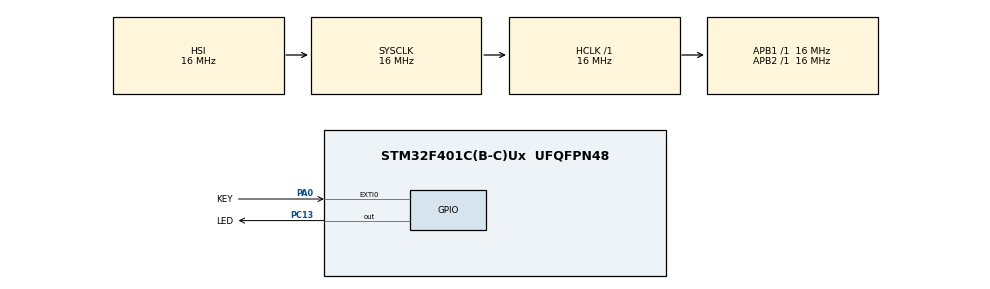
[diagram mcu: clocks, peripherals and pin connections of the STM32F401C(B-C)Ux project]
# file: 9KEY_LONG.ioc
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Mcu.Family=STM32F4
Mcu.Name=STM32F401C(B-C)Ux
Mcu.Package=UFQFPN48
NVIC.PriorityGroup=NVIC_PRIORITYGROUP_4
PA0-WKUP.GPIO_Label=KEY
PA0-WKUP.GPIO_PuPd=GPIO_PULLUP
PA0-WKUP.Signal=GPXTI0
PA13.Mode=Serial_Wire
PA13.Signal=SYS_JTMS-SWDIO
PA14.Mode=Serial_Wire
PA14.Signal=SYS_JTCK-SWCLK
PC13-ANTI_TAMP.GPIO_Label=LED
PC13-ANTI_TAMP.PinState=GPIO_PIN_SET
PC13-ANTI_TAMP.Signal=GPIO_Output
ProjectManager.HeapSize=0x200
ProjectManager.StackSize=0x400
ProjectManager.TargetToolchain=STM32CubeIDE
RCC.AHBFreq_Value=16000000
RCC.APB1Freq_Value=16000000
RCC.APB2Freq_Value=16000000
RCC.CortexFreq_Value=16000000
RCC.HSE_VALUE=25000000
RCC.HSI_VALUE=16000000
RCC.LSE_VALUE=32768
RCC.SYSCLKFreq_VALUE=16000000
RCC.VCOOutputFreq_Value=192000000
board=custom

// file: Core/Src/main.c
/* USER CODE BEGIN Header */
/**
  ******************************************************************************
  * @file           : main.c
  * @brief          : Main program body
  ******************************************************************************
  * @attention
  *
  * Copyright (c) 2022 STMicroelectronics.
  * All rights reserved.
  *
  * This software is licensed under terms that can be found in the LICENSE file
  * in the root directory of this software component.
  * If no LICENSE file comes with this software, it is provided AS-IS.
  *
  ******************************************************************************
  */
/* USER CODE END Header */
#include "main.h"

/* USER CODE BEGIN PTD */
typedef struct{
	uint32_t time;
	pinState level;
} buttonDef;
buttonDef key[3];

/* USER CODE END PTD */

/* USER CODE BEGIN PD */
#define LONG_KEY_MIN 3000 //3SEC
#define LONG_KEY_MAX 5000
#define DOUBLE_KEY_MIN 40
#define DOUBLE_KEY_MAX 120

#define KEY (!HAL_GPIO_ReadPin(KEY_GPIO_Port,KEY_Pin))

/* USER CODE END PD */

/* USER CODE BEGIN PV */
uint32_t curTime, oldTime;
uint32_t interval;

uint8_t oldKey = 0;
/* USER CODE END PV */

void SystemClock_Config(void);
static void MX_GPIO_Init(void);

/* USER CODE BEGIN 0 */
void HAL_GPIO_EXTI_Callback(uint16_t GPIO_Pin)
{
	pinState pin;
	uint8_t i;
/*
	if((KEY != oldKey) && KEY){
	    	__NOP();
	    }
	    oldKey = KEY;
*/
	if(GPIO_Pin == KEY_Pin)
	{
		curTime = HAL_GetTick();
		interval = curTime - oldTime;
		oldTime = curTime;

		pin = HAL_GPIO_ReadPin(KEY_GPIO_Port, KEY_Pin);
		__NOP();

		if(interval <= 2){
			__NOP();//noise
		} else {
			key[2].time = key[1].time;
			key[2].level = key[1].level;

			key[1].time = key[0].time;
			key[1].level = key[0].level;

			key[0].time = interval;
			key[0].level = pin;
		}

		if(key[0].level == GPIO_PIN_RESET && key[0].time >= LONG_KEY_MIN)
		{
			//LONG KEY
		} else if(key[0].level == GPIO_PIN_RESET && key[0].time < LONG_KEY_MIN)
		{
			//SHORT KEY
		}
	}
}
/* USER CODE END 0 */

int main(void)
{

  /* MCU Configuration--------------------------------------------------------*/

  /* Reset of all peripherals, Initializes the Flash interface and the Systick. */
  HAL_Init();

  /* Configure the system clock */
  SystemClock_Config();

  /* Initialize all configured peripherals */
  MX_GPIO_Init();

  /* Infinite loop */
  while (1)
  {

  }
}

void SystemClock_Config(void)
{
  RCC_OscInitTypeDef RCC_OscInitStruct = {0};
  RCC_ClkInitTypeDef RCC_ClkInitStruct = {0};

  /** Configure the main internal regulator output voltage
  */
  __HAL_RCC_PWR_CLK_ENABLE();
  __HAL_PWR_VOLTAGESCALING_CONFIG(PWR_REGULATOR_VOLTAGE_SCALE2);
  /** Initializes the RCC Oscillators according to the specified parameters
  * in the RCC_OscInitTypeDef structure.
  */
  RCC_OscInitStruct.OscillatorType = RCC_OSCILLATORTYPE_HSI;
  RCC_OscInitStruct.HSIState = RCC_HSI_ON;
  RCC_OscInitStruct.HSICalibrationValue = RCC_HSICALIBRATION_DEFAULT;
  RCC_OscInitStruct.PLL.PLLState = RCC_PLL_NONE;
  if (HAL_RCC_OscConfig(&RCC_OscInitStruct) != HAL_OK)
  {
    Error_Handler();
  }
  /** Initializes the CPU, AHB and APB buses clocks
  */
  RCC_ClkInitStruct.ClockType = RCC_CLOCKTYPE_HCLK|RCC_CLOCKTYPE_SYSCLK
                              |RCC_CLOCKTYPE_PCLK1|RCC_CLOCKTYPE_PCLK2;
  RCC_ClkInitStruct.SYSCLKSource = RCC_SYSCLKSOURCE_HSI;
  RCC_ClkInitStruct.AHBCLKDivider = RCC_SYSCLK_DIV1;
  RCC_ClkInitStruct.APB1CLKDivider = RCC_HCLK_DIV1;
  RCC_ClkInitStruct.APB2CLKDivider = RCC_HCLK_DIV1;

  if (HAL_RCC_ClockConfig(&RCC_ClkInitStruct, FLASH_LATENCY_0) != HAL_OK)
  {
    Error_Handler();
  }
}

static void MX_GPIO_Init(void)
{
  GPIO_InitTypeDef GPIO_InitStruct = {0};

  /* GPIO Ports Clock Enable */
  __HAL_RCC_GPIOC_CLK_ENABLE();
  __HAL_RCC_GPIOA_CLK_ENABLE();

  /*Configure GPIO pin Output Level */
  HAL_GPIO_WritePin(LED_GPIO_Port, LED_Pin, GPIO_PIN_SET);

  /*Configure GPIO pin : LED_Pin */
  GPIO_InitStruct.Pin = LED_Pin;
  GPIO_InitStruct.Mode = GPIO_MODE_OUTPUT_PP;
  GPIO_InitStruct.Pull = GPIO_NOPULL;
  GPIO_InitStruct.Speed = GPIO_SPEED_FREQ_LOW;
  HAL_GPIO_Init(LED_GPIO_Port, &GPIO_InitStruct);

  /*Configure GPIO pin : KEY_Pin */
  GPIO_InitStruct.Pin = KEY_Pin;
  GPIO_InitStruct.Mode = GPIO_MODE_IT_RISING;
  GPIO_InitStruct.Pull = GPIO_PULLUP;
  HAL_GPIO_Init(KEY_GPIO_Port, &GPIO_InitStruct);

}

void Error_Handler(void)
{
  __disable_irq();
  while (1)
  {
  }
}
